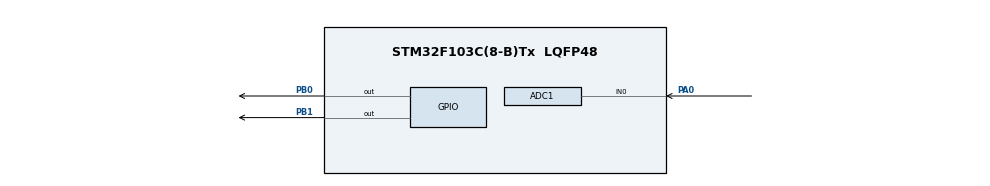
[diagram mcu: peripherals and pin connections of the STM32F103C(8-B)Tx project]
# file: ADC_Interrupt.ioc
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ADC1.Channel-0\#ChannelRegularConversion=ADC_CHANNEL_0
ADC1.ContinuousConvMode=DISABLE
ADC1.NbrOfConversion=1
ADC1.NbrOfConversionFlag=1
ADC1.Rank-0\#ChannelRegularConversion=1
ADC1.SamplingTime-0\#ChannelRegularConversion=ADC_SAMPLETIME_1CYCLE_5
ADC1.master=1
Mcu.Family=STM32F1
Mcu.Name=STM32F103C(8-B)Tx
Mcu.Package=LQFP48
NVIC.ADC1_2_IRQn=true\:0\:0\:false\:false\:true\:true\:true\:true
NVIC.PriorityGroup=NVIC_PRIORITYGROUP_4
PA0-WKUP.Signal=ADCx_IN0
PA13.Mode=Serial_Wire
PA13.Signal=SYS_JTMS-SWDIO
PA14.Mode=Serial_Wire
PA14.Signal=SYS_JTCK-SWCLK
PB0.Signal=GPIO_Output
PB1.Signal=GPIO_Output
PD0-OSC_IN.Mode=HSE-External-Oscillator
PD0-OSC_IN.Signal=RCC_OSC_IN
PD1-OSC_OUT.Mode=HSE-External-Oscillator
PD1-OSC_OUT.Signal=RCC_OSC_OUT
ProjectManager.HeapSize=0x200
ProjectManager.StackSize=0x400
ProjectManager.TargetToolchain=STM32CubeIDE
RCC.APB1Freq_Value=8000000
RCC.APB2Freq_Value=8000000
SH.ADCx_IN0.0=ADC1_IN0,IN0
board=custom

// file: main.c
/* USER CODE BEGIN Header */
/**
  ******************************************************************************
  * @file           : main.c
  * @brief          : Main program body (ADC Interrupt + LED Blink)
  ******************************************************************************
  * @attention
  *
  * STM32F103C8T6
  * Potensiometer di PA0 (ADC1 Channel 0)
  * LED1 di PB0 → mode blink (polling/delay)
  * LED2 di PB1 → dikontrol oleh interrupt ADC
  *
  ******************************************************************************
  */
/* USER CODE END Header */

#include "main.h"

ADC_HandleTypeDef hadc1;

/* USER CODE BEGIN PV */
uint32_t adcValue = 0;   // Nilai hasil konversi ADC
/* USER CODE END PV */

void SystemClock_Config(void);
static void MX_GPIO_Init(void);
static void MX_ADC1_Init(void);

/* USER CODE BEGIN 0 */
/* Callback interrupt ADC */
void HAL_ADC_ConvCpltCallback(ADC_HandleTypeDef* hadc)
{
  if (hadc->Instance == ADC1)
  {
    adcValue = HAL_ADC_GetValue(hadc);

    // LED2 (PB1) akan ON jika potensiometer > 2000
    if (adcValue > 2000)
      HAL_GPIO_WritePin(GPIOB, GPIO_PIN_0, GPIO_PIN_SET);
    else
      HAL_GPIO_WritePin(GPIOB, GPIO_PIN_0, GPIO_PIN_RESET);

    // Restart ADC interrupt agar terus membaca
    HAL_ADC_Start_IT(hadc);
  }
}
/* USER CODE END 0 */

int main(void)
{
  /* MCU Configuration--------------------------------------------------------*/
  HAL_Init();
  SystemClock_Config();
  MX_GPIO_Init();
  MX_ADC1_Init();

  /* USER CODE BEGIN 2 */
  // Mulai ADC dalam mode interrupt
  HAL_ADC_Start_IT(&hadc1);
  /* USER CODE END 2 */

  /* Infinite loop */
  while (1)
  {
    /* ======== ZONA LED1 (Polling dengan Delay) ======== */
    for (int i = 0; i < 3; i++)  // LED1 kedip 3 kali (3 detik)
    {
      HAL_GPIO_WritePin(GPIOB, GPIO_PIN_1, GPIO_PIN_SET);
      HAL_Delay(500);
      HAL_GPIO_WritePin(GPIOB, GPIO_PIN_1, GPIO_PIN_RESET);
      HAL_Delay(500);
    }

    // LED2 akan tetap merespons ADC secara real-time (via interrupt)
  }
}

void SystemClock_Config(void)
{
  RCC_OscInitTypeDef RCC_OscInitStruct = {0};
  RCC_ClkInitTypeDef RCC_ClkInitStruct = {0};
  RCC_PeriphCLKInitTypeDef PeriphClkInit = {0};

  /* Konfigurasi clock HSI (8 MHz) */
  RCC_OscInitStruct.OscillatorType = RCC_OSCILLATORTYPE_HSI;
  RCC_OscInitStruct.HSIState = RCC_HSI_ON;
  RCC_OscInitStruct.HSICalibrationValue = RCC_HSICALIBRATION_DEFAULT;
  RCC_OscInitStruct.PLL.PLLState = RCC_PLL_NONE;
  HAL_RCC_OscConfig(&RCC_OscInitStruct);

  /* Konfigurasi sistem clock */
  RCC_ClkInitStruct.ClockType = RCC_CLOCKTYPE_HCLK | RCC_CLOCKTYPE_SYSCLK |
                                RCC_CLOCKTYPE_PCLK1 | RCC_CLOCKTYPE_PCLK2;
  RCC_ClkInitStruct.SYSCLKSource = RCC_SYSCLKSOURCE_HSI;
  RCC_ClkInitStruct.AHBCLKDivider = RCC_SYSCLK_DIV1;
  RCC_ClkInitStruct.APB1CLKDivider = RCC_HCLK_DIV1;
  RCC_ClkInitStruct.APB2CLKDivider = RCC_HCLK_DIV1;
  HAL_RCC_ClockConfig(&RCC_ClkInitStruct, FLASH_LATENCY_0);

  /* Konfigurasi clock untuk ADC */
  PeriphClkInit.PeriphClockSelection = RCC_PERIPHCLK_ADC;
  PeriphClkInit.AdcClockSelection = RCC_ADCPCLK2_DIV2;
  HAL_RCCEx_PeriphCLKConfig(&PeriphClkInit);
}

static void MX_ADC1_Init(void)
{
  ADC_ChannelConfTypeDef sConfig = {0};

  hadc1.Instance = ADC1;
  hadc1.Init.ScanConvMode = ADC_SCAN_DISABLE;
  hadc1.Init.ContinuousConvMode = DISABLE;
  hadc1.Init.DiscontinuousConvMode = DISABLE;
  hadc1.Init.ExternalTrigConv = ADC_SOFTWARE_START;
  hadc1.Init.DataAlign = ADC_DATAALIGN_RIGHT;
  hadc1.Init.NbrOfConversion = 1;

  if (HAL_ADC_Init(&hadc1) != HAL_OK)
  {
    Error_Handler();
  }

  /* Konfigurasi channel ADC (PA0) */
  sConfig.Channel = ADC_CHANNEL_0;
  sConfig.Rank = ADC_REGULAR_RANK_1;
  sConfig.SamplingTime = ADC_SAMPLETIME_55CYCLES_5;

  if (HAL_ADC_ConfigChannel(&hadc1, &sConfig) != HAL_OK)
  {
    Error_Handler();
  }
}

static void MX_GPIO_Init(void)
{
  GPIO_InitTypeDef GPIO_InitStruct = {0};

  __HAL_RCC_GPIOD_CLK_ENABLE();
  __HAL_RCC_GPIOA_CLK_ENABLE();
  __HAL_RCC_GPIOB_CLK_ENABLE();

  /* Inisialisasi LED1 (PB0) dan LED2 (PB1) sebagai output */
  HAL_GPIO_WritePin(GPIOB, GPIO_PIN_0 | GPIO_PIN_1, GPIO_PIN_RESET);
  GPIO_InitStruct.Pin = GPIO_PIN_0 | GPIO_PIN_1;
  GPIO_InitStruct.Mode = GPIO_MODE_OUTPUT_PP;
  GPIO_InitStruct.Pull = GPIO_NOPULL;
  GPIO_InitStruct.Speed = GPIO_SPEED_FREQ_LOW;
  HAL_GPIO_Init(GPIOB, &GPIO_InitStruct);
}

/**
  * @brief  Error Handler
  * @retval None
  */
void Error_Handler(void)
{
  __disable_irq();
  while (1)
  {
  }
}
